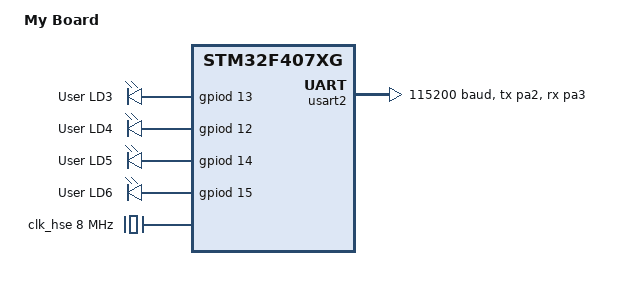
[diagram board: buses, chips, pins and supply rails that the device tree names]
/dts-v1/;
#include <st/f4/stm32f407Xg.dtsi>
#include <st/f4/stm32f407v(e-g)tx-pinctrl.dtsi>

/ {
	model = "My Board";
	compatible = "my_board";

  aliases {
		led0 = &green_led_4;
		led1 = &orange_led_3;
		led2 = &red_led_5;
		led3 = &blue_led_6;
	};


	chosen {
    zephyr,console = &usart2;
    zephyr,shell-uart = &usart2;
		zephyr,sram = &sram0;
    zephyr,ccm = &ccm0;
		zephyr,flash = &flash0;
	};

	leds {
		compatible = "gpio-leds";

		orange_led_3: led_3 {
			gpios = <&gpiod 13 GPIO_ACTIVE_HIGH>;
			label = "User LD3";
		};

		green_led_4: led_4 {
			gpios = <&gpiod 12 GPIO_ACTIVE_HIGH>;
			label = "User LD4";
		};

		red_led_5: led_5 {
			gpios = <&gpiod 14 GPIO_ACTIVE_HIGH>;
			label = "User LD5";
		};

		blue_led_6: led_6 {
			gpios = <&gpiod 15 GPIO_ACTIVE_HIGH>;
			label = "User LD6";
		};
	};
};

&clk_lsi {
  status = "okay";
};

&clk_hse {
  clock-frequency = <DT_FREQ_M(8)>;
  status = "okay";
};

&pll {
  div-m = <8>;
  mul-n = <336>;
  div-p = <2>;
  div-q = <7>;
  clocks = <&clk_hse>;
  status = "okay";
};

&rcc {
  clocks = <&pll>;
  clock-frequency = <DT_FREQ_M(168)>;
  ahb-prescaler = <1>;
  apb1-prescaler = <4>;
  apb2-prescaler = <2>;
};

&usart2 {
  pinctrl-0 = <&usart2_tx_pa2 &usart2_rx_pa3>;
  pinctrl-names = "default";
  current-speed = <115200>;
  status = "okay";
};
